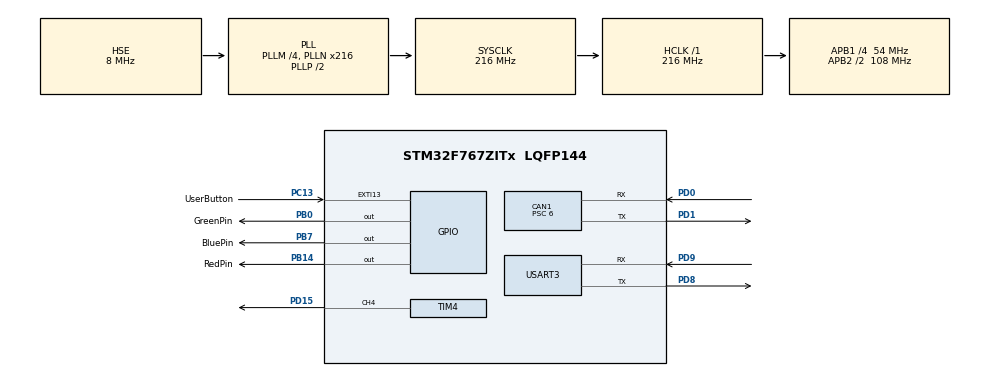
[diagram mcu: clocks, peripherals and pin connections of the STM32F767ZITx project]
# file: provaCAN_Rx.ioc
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CAN1.BS1=CAN_BS1_15TQ
CAN1.BS2=CAN_BS2_2TQ
CAN1.CalculateTimeQuantum=111.11111111111111
CAN1.Prescaler=6
Dma.Request0=USART3_TX
Dma.USART3_TX.0.Direction=DMA_MEMORY_TO_PERIPH
Dma.USART3_TX.0.FIFOMode=DMA_FIFOMODE_DISABLE
Dma.USART3_TX.0.Instance=DMA1_Stream3
Dma.USART3_TX.0.MemDataAlignment=DMA_MDATAALIGN_BYTE
Dma.USART3_TX.0.MemInc=DMA_MINC_ENABLE
Dma.USART3_TX.0.Mode=DMA_NORMAL
Dma.USART3_TX.0.PeriphDataAlignment=DMA_PDATAALIGN_BYTE
Dma.USART3_TX.0.PeriphInc=DMA_PINC_DISABLE
Dma.USART3_TX.0.Priority=DMA_PRIORITY_LOW
Mcu.Family=STM32F7
Mcu.Name=STM32F767ZITx
Mcu.Package=LQFP144
NVIC.CAN1_RX0_IRQn=true\:0\:0\:false\:false\:true\:true\:true
NVIC.CAN1_RX1_IRQn=true\:0\:0\:false\:false\:true\:true\:true
NVIC.CAN1_TX_IRQn=true\:0\:0\:false\:false\:true\:true\:true
NVIC.DMA1_Stream3_IRQn=true\:0\:0\:false\:false\:true\:false\:true
NVIC.PriorityGroup=NVIC_PRIORITYGROUP_4
NVIC.TIM2_IRQn=true\:0\:0\:false\:false\:true\:true\:true
NVIC.USART3_IRQn=true\:0\:0\:false\:false\:true\:true\:true
PB0.GPIO_Label=GreenPin
PB0.Signal=GPIO_Output
PB14.GPIO_Label=RedPin
PB14.Signal=GPIO_Output
PB7.GPIO_Label=BluePin
PB7.Signal=GPIO_Output
PC13.GPIO_Label=UserButton
PC13.GPIO_ModeDefaultEXTI=GPIO_MODE_IT_RISING
PC13.Signal=GPXTI13
PD0.Mode=Master
PD0.Signal=CAN1_RX
PD1.Mode=Master
PD1.Signal=CAN1_TX
PD15.Signal=S_TIM4_CH4
PD8.Mode=Asynchronous
PD8.Signal=USART3_TX
PD9.Mode=Asynchronous
PD9.Signal=USART3_RX
PH0/OSC_IN.Mode=HSE-External-Oscillator
PH0/OSC_IN.Signal=RCC_OSC_IN
PH1/OSC_OUT.Mode=HSE-External-Oscillator
PH1/OSC_OUT.Signal=RCC_OSC_OUT
ProjectManager.HeapSize=0x200
ProjectManager.StackSize=0x400
ProjectManager.TargetToolchain=MDK-ARM V5
RCC.48MHZClocksFreq_Value=24000000
RCC.AHBFreq_Value=216000000
RCC.APB1CLKDivider=RCC_HCLK_DIV4
RCC.APB1Freq_Value=54000000
RCC.APB1TimFreq_Value=108000000
RCC.APB2CLKDivider=RCC_HCLK_DIV2
RCC.APB2Freq_Value=108000000
RCC.APB2TimFreq_Value=216000000
RCC.CortexFreq_Value=216000000
RCC.HCLKFreq_Value=216000000
RCC.HSE_VALUE=8000000
RCC.HSI_VALUE=16000000
RCC.LSE_VALUE=32768
RCC.PLLM=4
RCC.PLLMUL=RCC_PLL_MUL9
RCC.PLLN=216
RCC.PLLQ=4
RCC.PLLSourceVirtual=RCC_PLLSOURCE_HSE
RCC.PRESCALERUSB=RCC_USBCLKSOURCE_PLL_DIV1_5
RCC.SYSCLKFreq_VALUE=216000000
RCC.SYSCLKSource=RCC_SYSCLKSOURCE_PLLCLK
RCC.SYSCLKSourceVirtual=RCC_SYSCLKSOURCE_PLLCLK
RCC.USBFreq_Value=108000000
RCC.VCOOutputFreq_Value=432000000
SH.S_TIM4_CH4.0=TIM4_CH4,PWM Generation4 CH4
TIM2.Period=108-1
TIM2.Prescaler=1000-1
TIM4.Channel-PWM\ Generation4\ CH4=TIM_CHANNEL_4
TIM4.Period=2000-1
TIM4.Prescaler=1080-1
USART3.VirtualMode-Asynchronous=VM_ASYNC
VP_TIM2_VS_ClockSourceINT.Mode=Internal
VP_TIM4_VS_ClockSourceINT.Mode=Internal
board=NUCLEO-F767ZI

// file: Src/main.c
/* USER CODE BEGIN Header */
/**
  ******************************************************************************
  * @file           : main.c
  * @brief          : Main program body
  ******************************************************************************
  * @attention
  *
  * <h2><center>&copy; Copyright (c) 2019 STMicroelectronics.
  * All rights reserved.</center></h2>
  *
  * This software component is licensed by ST under BSD 3-Clause license,
  * the "License"; You may not use this file except in compliance with the
  * License. You may obtain a copy of the License at:
  *                        opensource.org/licenses/BSD-3-Clause
  *
  ******************************************************************************
  */
/* USER CODE END Header */

#include "main.h"
#include "can.h"
#include "dma.h"
#include "gfxsimulator.h"
#include "tim.h"
#include "usart.h"
#include "gpio.h"

void SystemClock_Config(void);

/* USER CODE BEGIN 0 */
int timer2_counter1 = 0;
/* USER CODE END 0 */

int main(void)
{

  /* MCU Configuration--------------------------------------------------------*/

  /* Reset of all peripherals, Initializes the Flash interface and the Systick. */
  HAL_Init();

  /* Configure the system clock */
  SystemClock_Config();

  /* Initialize all configured peripherals */
  MX_GPIO_Init();
  MX_DMA_Init();
  MX_USART3_UART_Init();
  MX_TIM2_Init();
  MX_GFXSIMULATOR_Init();
  MX_TIM4_Init();
  MX_CAN1_Init();
  /* USER CODE BEGIN 2 */
	HAL_TIM_Base_Start_IT(&htim2);
	CAN1_Start();
	HAL_Delay(250);
  /* USER CODE END 2 */

  /* Infinite loop */
  while (1)
  {

  }
}

void SystemClock_Config(void)
{
  RCC_OscInitTypeDef RCC_OscInitStruct = {0};
  RCC_ClkInitTypeDef RCC_ClkInitStruct = {0};
  RCC_PeriphCLKInitTypeDef PeriphClkInitStruct = {0};

  /** Configure the main internal regulator output voltage
  */
  __HAL_RCC_PWR_CLK_ENABLE();
  __HAL_PWR_VOLTAGESCALING_CONFIG(PWR_REGULATOR_VOLTAGE_SCALE1);
  /** Initializes the CPU, AHB and APB busses clocks
  */
  RCC_OscInitStruct.OscillatorType = RCC_OSCILLATORTYPE_HSE;
  RCC_OscInitStruct.HSEState = RCC_HSE_ON;
  RCC_OscInitStruct.PLL.PLLState = RCC_PLL_ON;
  RCC_OscInitStruct.PLL.PLLSource = RCC_PLLSOURCE_HSE;
  RCC_OscInitStruct.PLL.PLLM = 4;
  RCC_OscInitStruct.PLL.PLLN = 216;
  RCC_OscInitStruct.PLL.PLLP = RCC_PLLP_DIV2;
  RCC_OscInitStruct.PLL.PLLQ = 4;
  if (HAL_RCC_OscConfig(&RCC_OscInitStruct) != HAL_OK)
  {
    Error_Handler();
  }
  /** Activate the Over-Drive mode
  */
  if (HAL_PWREx_EnableOverDrive() != HAL_OK)
  {
    Error_Handler();
  }
  /** Initializes the CPU, AHB and APB busses clocks
  */
  RCC_ClkInitStruct.ClockType = RCC_CLOCKTYPE_HCLK|RCC_CLOCKTYPE_SYSCLK
                              |RCC_CLOCKTYPE_PCLK1|RCC_CLOCKTYPE_PCLK2;
  RCC_ClkInitStruct.SYSCLKSource = RCC_SYSCLKSOURCE_PLLCLK;
  RCC_ClkInitStruct.AHBCLKDivider = RCC_SYSCLK_DIV1;
  RCC_ClkInitStruct.APB1CLKDivider = RCC_HCLK_DIV4;
  RCC_ClkInitStruct.APB2CLKDivider = RCC_HCLK_DIV2;

  if (HAL_RCC_ClockConfig(&RCC_ClkInitStruct, FLASH_LATENCY_7) != HAL_OK)
  {
    Error_Handler();
  }
  PeriphClkInitStruct.PeriphClockSelection = RCC_PERIPHCLK_USART3;
  PeriphClkInitStruct.Usart3ClockSelection = RCC_USART3CLKSOURCE_PCLK1;
  if (HAL_RCCEx_PeriphCLKConfig(&PeriphClkInitStruct) != HAL_OK)
  {
    Error_Handler();
  }
}

/* USER CODE BEGIN 4 */
void HAL_TIM_PeriodElapsedCallback(TIM_HandleTypeDef *htim)
{
	if (htim->Instance == htim2.Instance)
	{
		timer2_counter1++;
		//uint32_t emptyMailboxes = HAL_CAN_GetTxMailboxesFreeLevel(&hcan1);

		if(timer2_counter1 >= 500)
		{
			//HAL_GPIO_TogglePin(RedPin_GPIO_Port, RedPin_Pin);
			CAN1_Send_Nucleo_F7_Packet();
			timer2_counter1 = 0;
		}

	}
}
/* USER CODE END 4 */

void Error_Handler(void)
{
}

/************************ (C) COPYRIGHT STMicroelectronics *****END OF FILE****/
